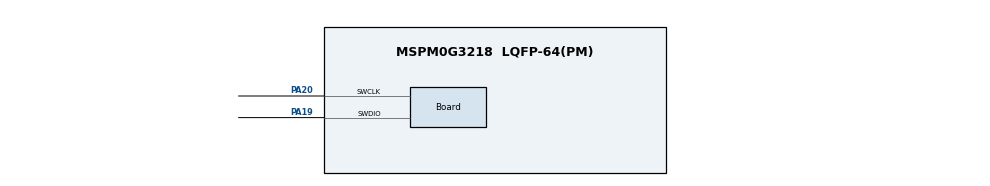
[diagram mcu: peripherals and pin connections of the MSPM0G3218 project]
//@cliArgs --device "MSPM0G321X" --package "LQFP-64(PM)" --part "Default"
//@v2CliArgs --device "MSPM0G3218" --package "LQFP-64(PM)"
// @cliArgs --board /ti/boards/LP_MSPM0G3218 --rtos nortos

/**
 * Import the modules used in this configuration.
 */
const ADC12  = scripting.addModule("/ti/driverlib/ADC12", {}, false);
const ADC121 = ADC12.addInstance();
const Board  = scripting.addModule("/ti/driverlib/Board");
const SYSCTL = scripting.addModule("/ti/driverlib/SYSCTL");

/**
 * Write custom configuration values to the imported modules.
 */
ADC121.$name                      = "ADC12_0";
ADC121.sampClkSrc                 = "DL_ADC12_CLOCK_ULPCLK";
ADC121.sampClkDiv                 = "DL_ADC12_CLOCK_DIVIDE_8";
ADC121.powerDownMode              = "DL_ADC12_POWER_DOWN_MODE_MANUAL";
ADC121.samplingOperationMode      = "sequence";
ADC121.endAdd                     = 3;
ADC121.enabledInterrupts          = ["DL_ADC12_INTERRUPT_MEM3_RESULT_LOADED"];
ADC121.sampleTime0                = "40 us";
ADC121.adcMem3chansel             = "DL_ADC12_INPUT_CHAN_7";
ADC121.adcMem2chansel             = "DL_ADC12_INPUT_CHAN_3";
ADC121.adcMem0chansel             = "DL_ADC12_INPUT_CHAN_5";
ADC121.adcMem1chansel             = "DL_ADC12_INPUT_CHAN_0";
ADC121.peripheral.$assign         = "ADC0";
ADC121.peripheral.adcPin5.$assign = "PB24";
ADC121.peripheral.adcPin0.$assign = "PA27";
ADC121.peripheral.adcPin3.$assign = "PA24";

Board.peripheral.$assign          = "DEBUGSS";
Board.peripheral.swclkPin.$assign = "PA20";
Board.peripheral.swdioPin.$assign = "PA19";

SYSCTL.forceDefaultClkConfig = true;
SYSCTL.peripheral.$assign    = "SYSCTL";

const ProjectConfig              = scripting.addModule("/ti/project_config/ProjectConfig", {}, false);
ProjectConfig.migrationCondition = true;
